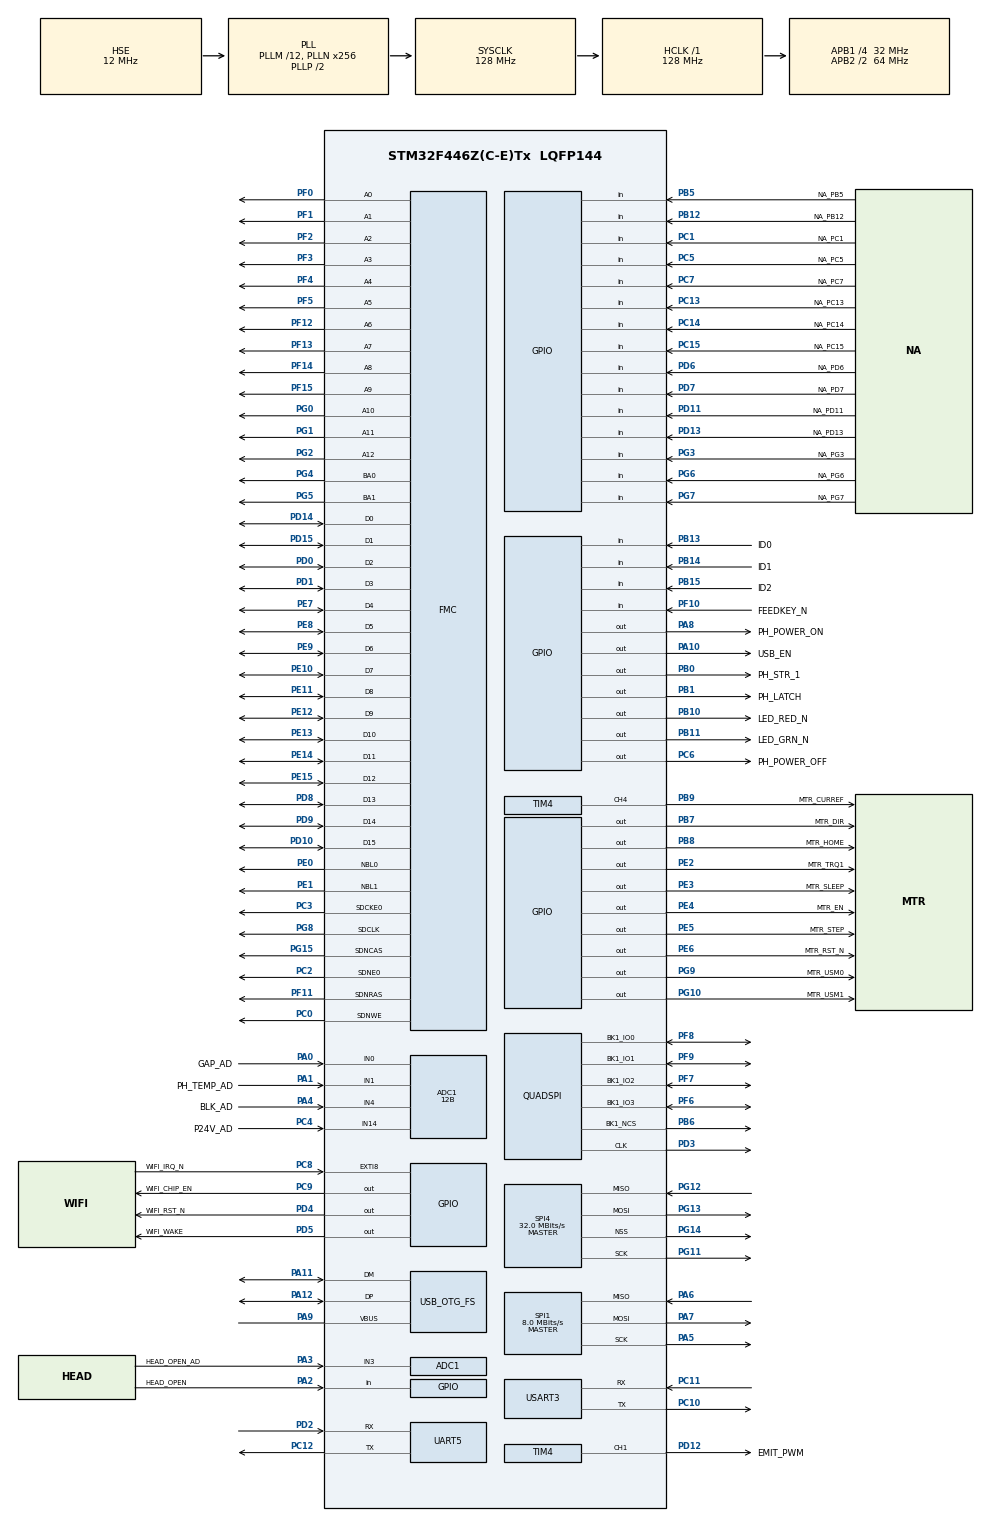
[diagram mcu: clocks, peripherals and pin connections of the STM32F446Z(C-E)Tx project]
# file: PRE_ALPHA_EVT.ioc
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ADC1.Channel-0\#ChannelRegularConversion=ADC_CHANNEL_0
ADC1.Channel-1\#ChannelRegularConversion=ADC_CHANNEL_1
ADC1.Channel-2\#ChannelRegularConversion=ADC_CHANNEL_3
ADC1.Channel-3\#ChannelRegularConversion=ADC_CHANNEL_14
ADC1.Channel-4\#ChannelRegularConversion=ADC_CHANNEL_TEMPSENSOR
ADC1.Channel-6\#ChannelRegularConversion=ADC_CHANNEL_4
ADC1.ClockPrescaler=ADC_CLOCK_SYNC_PCLK_DIV2
ADC1.ContinuousConvMode=ENABLE
ADC1.DMAContinuousRequests=ENABLE
ADC1.DataAlign=ADC_DATAALIGN_RIGHT
ADC1.DiscontinuousConvMode=DISABLE
ADC1.EOCSelection=ADC_EOC_SEQ_CONV
ADC1.EnableAnalogWatchDog=false
ADC1.ExternalTrigConv=ADC_SOFTWARE_START
ADC1.ExternalTrigConvEdge=ADC_EXTERNALTRIGCONVEDGE_NONE
ADC1.InjNumberOfConversion=0
ADC1.NbrOfConversion=6
ADC1.NbrOfConversionFlag=1
ADC1.Rank-0\#ChannelRegularConversion=1
ADC1.Rank-1\#ChannelRegularConversion=2
ADC1.Rank-2\#ChannelRegularConversion=3
ADC1.Rank-3\#ChannelRegularConversion=4
ADC1.Rank-4\#ChannelRegularConversion=5
ADC1.Rank-6\#ChannelRegularConversion=6
ADC1.Resolution=ADC_RESOLUTION_12B
ADC1.SamplingTime-0\#ChannelRegularConversion=ADC_SAMPLETIME_112CYCLES
ADC1.SamplingTime-1\#ChannelRegularConversion=ADC_SAMPLETIME_112CYCLES
ADC1.SamplingTime-2\#ChannelRegularConversion=ADC_SAMPLETIME_112CYCLES
ADC1.SamplingTime-3\#ChannelRegularConversion=ADC_SAMPLETIME_112CYCLES
ADC1.SamplingTime-4\#ChannelRegularConversion=ADC_SAMPLETIME_480CYCLES
ADC1.SamplingTime-6\#ChannelRegularConversion=ADC_SAMPLETIME_112CYCLES
ADC1.ScanConvMode=ENABLE
ADC1.master=1
Dma.ADC1.3.Direction=DMA_PERIPH_TO_MEMORY
Dma.ADC1.3.FIFOMode=DMA_FIFOMODE_DISABLE
Dma.ADC1.3.Instance=DMA2_Stream0
Dma.ADC1.3.MemDataAlignment=DMA_MDATAALIGN_WORD
Dma.ADC1.3.MemInc=DMA_MINC_ENABLE
Dma.ADC1.3.Mode=DMA_CIRCULAR
Dma.ADC1.3.PeriphDataAlignment=DMA_PDATAALIGN_WORD
Dma.ADC1.3.PeriphInc=DMA_PINC_DISABLE
Dma.ADC1.3.Priority=DMA_PRIORITY_VERY_HIGH
Dma.MEMTOMEM.0.Direction=DMA_MEMORY_TO_MEMORY
Dma.MEMTOMEM.0.FIFOMode=DMA_FIFOMODE_ENABLE
Dma.MEMTOMEM.0.FIFOThreshold=DMA_FIFO_THRESHOLD_FULL
Dma.MEMTOMEM.0.Instance=DMA2_Stream2
Dma.MEMTOMEM.0.MemBurst=DMA_MBURST_SINGLE
Dma.MEMTOMEM.0.MemDataAlignment=DMA_MDATAALIGN_WORD
Dma.MEMTOMEM.0.MemInc=DMA_MINC_ENABLE
Dma.MEMTOMEM.0.Mode=DMA_NORMAL
Dma.MEMTOMEM.0.PeriphBurst=DMA_PBURST_SINGLE
Dma.MEMTOMEM.0.PeriphDataAlignment=DMA_PDATAALIGN_WORD
Dma.MEMTOMEM.0.PeriphInc=DMA_PINC_ENABLE
Dma.MEMTOMEM.0.Priority=DMA_PRIORITY_MEDIUM
Dma.Request0=MEMTOMEM
Dma.Request1=SPI4_TX
Dma.Request2=SPI4_RX
Dma.Request3=ADC1
Dma.Request4=SPI1_TX
Dma.SPI1_TX.4.Direction=DMA_MEMORY_TO_PERIPH
Dma.SPI1_TX.4.FIFOMode=DMA_FIFOMODE_DISABLE
Dma.SPI1_TX.4.Instance=DMA2_Stream5
Dma.SPI1_TX.4.MemDataAlignment=DMA_MDATAALIGN_BYTE
Dma.SPI1_TX.4.MemInc=DMA_MINC_ENABLE
Dma.SPI1_TX.4.Mode=DMA_NORMAL
Dma.SPI1_TX.4.PeriphDataAlignment=DMA_PDATAALIGN_BYTE
Dma.SPI1_TX.4.PeriphInc=DMA_PINC_DISABLE
Dma.SPI1_TX.4.Priority=DMA_PRIORITY_HIGH
Dma.SPI4_RX.2.Direction=DMA_PERIPH_TO_MEMORY
Dma.SPI4_RX.2.FIFOMode=DMA_FIFOMODE_DISABLE
Dma.SPI4_RX.2.Instance=DMA2_Stream3
Dma.SPI4_RX.2.MemDataAlignment=DMA_MDATAALIGN_BYTE
Dma.SPI4_RX.2.MemInc=DMA_MINC_ENABLE
Dma.SPI4_RX.2.Mode=DMA_NORMAL
Dma.SPI4_RX.2.PeriphDataAlignment=DMA_PDATAALIGN_BYTE
Dma.SPI4_RX.2.PeriphInc=DMA_PINC_DISABLE
Dma.SPI4_RX.2.Priority=DMA_PRIORITY_LOW
Dma.SPI4_TX.1.Direction=DMA_MEMORY_TO_PERIPH
Dma.SPI4_TX.1.FIFOMode=DMA_FIFOMODE_DISABLE
Dma.SPI4_TX.1.Instance=DMA2_Stream4
Dma.SPI4_TX.1.MemDataAlignment=DMA_MDATAALIGN_BYTE
Dma.SPI4_TX.1.MemInc=DMA_MINC_ENABLE
Dma.SPI4_TX.1.Mode=DMA_NORMAL
Dma.SPI4_TX.1.PeriphDataAlignment=DMA_PDATAALIGN_BYTE
Dma.SPI4_TX.1.PeriphInc=DMA_PINC_DISABLE
Dma.SPI4_TX.1.Priority=DMA_PRIORITY_LOW
FMC.CASLatency1=FMC_SDRAM_CAS_LATENCY_3
FMC.ExitSelfRefreshDelay1=4
FMC.LoadToActiveDelay1=3
FMC.RCDDelay1=1
FMC.RPDelay1=1
FMC.RPDelay2=1
FMC.RowCycleDelay1=3
FMC.RowCycleDelay2=3
FMC.SDClockPeriod1=FMC_SDRAM_CLOCK_PERIOD_3
FMC.SDClockPeriod2=FMC_SDRAM_CLOCK_PERIOD_3
FMC.SelfRefreshTime1=2
FMC.WriteRecoveryTime1=2
Mcu.Family=STM32F4
Mcu.Name=STM32F446Z(C-E)Tx
Mcu.Package=LQFP144
NVIC.ADC_IRQn=true\:2\:0\:true\:false\:true\:true
NVIC.DMA2_Stream0_IRQn=true\:4\:0\:true\:false\:true\:false
NVIC.DMA2_Stream2_IRQn=true\:5\:0\:true\:false\:true\:true
NVIC.DMA2_Stream3_IRQn=true\:4\:0\:true\:false\:true\:false
NVIC.DMA2_Stream4_IRQn=true\:4\:0\:true\:false\:true\:false
NVIC.DMA2_Stream5_IRQn=true\:0\:0\:false\:false\:true\:false
NVIC.OTG_FS_IRQn=true\:3\:0\:true\:false\:true\:false
NVIC.PriorityGroup=NVIC_PRIORITYGROUP_4
NVIC.TIM2_IRQn=true\:3\:0\:true\:false\:true\:true
NVIC.TIM3_IRQn=true\:4\:0\:true\:false\:true\:true
NVIC.TIM5_IRQn=true\:4\:0\:true\:false\:true\:true
NVIC.USART3_IRQn=true\:0\:0\:false\:false\:true\:true
PA0-WKUP.GPIO_Label=GAP_AD
PA0-WKUP.Signal=ADCx_IN0
PA1.GPIO_Label=PH_TEMP_AD
PA1.Signal=ADCx_IN1
PA10.GPIO_Label=USB_EN
PA10.Signal=GPIO_Output
PA11.Mode=Device_Only
PA11.Signal=USB_OTG_FS_DM
PA12.Mode=Device_Only
PA12.Signal=USB_OTG_FS_DP
PA13.Mode=JTAG_5_pins
PA13.Signal=SYS_JTMS-SWDIO
PA14.Mode=JTAG_5_pins
PA14.Signal=SYS_JTCK-SWCLK
PA15.Mode=JTAG_5_pins
PA15.Signal=SYS_JTDI
PA2.GPIO_Label=HEAD_OPEN
PA2.Signal=GPIO_Input
PA3.GPIO_Label=HEAD_OPEN_AD
PA3.Signal=ADCx_IN3
PA4.GPIO_Label=BLK_AD
PA4.Signal=ADCx_IN4
PA5.Mode=Full_Duplex_Master
PA5.Signal=SPI1_SCK
PA6.Mode=Full_Duplex_Master
PA6.Signal=SPI1_MISO
PA7.Mode=Full_Duplex_Master
PA7.Signal=SPI1_MOSI
PA8.GPIO_Label=PH_POWER_ON
PA8.Signal=GPIO_Output
PA9.Mode=Activate_VBUS
PA9.Signal=USB_OTG_FS_VBUS
PB0.GPIO_Label=PH_STR_1
PB0.Signal=GPIO_Output
PB1.GPIO_Label=PH_LATCH
PB1.Signal=GPIO_Output
PB10.GPIO_Label=LED_RED_N
PB10.PinState=GPIO_PIN_SET
PB10.Signal=GPIO_Output
PB11.GPIO_Label=LED_GRN_N
PB11.PinState=GPIO_PIN_SET
PB11.Signal=GPIO_Output
PB12.GPIO_Label=NA_PB12
PB12.Signal=GPIO_Input
PB13.GPIO_Label=ID0
PB13.Signal=GPIO_Input
PB14.GPIO_Label=ID1
PB14.Signal=GPIO_Input
PB15.GPIO_Label=ID2
PB15.Signal=GPIO_Input
PB3.Mode=JTAG_5_pins
PB3.Signal=SYS_JTDO-SWO
PB4.Mode=JTAG_5_pins
PB4.Signal=SYS_JTRST
PB5.GPIO_Label=NA_PB5
PB5.Signal=GPIO_Input
PB6.Mode=Single Bank 1
PB6.Signal=QUADSPI_BK1_NCS
PB7.GPIO_Label=MTR_DIR
PB7.Signal=GPIO_Output
PB8.GPIO_Label=MTR_HOME
PB8.Signal=GPIO_Output
PB9.GPIO_Label=MTR_CURREF
PB9.GPIO_PuPd=GPIO_PULLUP
PB9.Signal=S_TIM4_CH4
PC0.Signal=FMC_SDNWE
PC1.GPIO_Label=NA_PC1
PC1.Signal=GPIO_Input
PC10.Mode=Asynchronous
PC10.Signal=USART3_TX
PC11.Mode=Asynchronous
PC11.Signal=USART3_RX
PC12.Mode=Asynchronous
PC12.Signal=UART5_TX
PC13.GPIO_Label=NA_PC13
PC13.Signal=GPIO_Input
PC14-OSC32_IN.GPIO_Label=NA_PC14
PC14-OSC32_IN.Signal=GPIO_Input
PC15-OSC32_OUT.GPIO_Label=NA_PC15
PC15-OSC32_OUT.Signal=GPIO_Input
PC2.Mode=SdramChipSelect1_1
PC2.Signal=FMC_SDNE0
PC3.Mode=SdramChipSelect1_1
PC3.Signal=FMC_SDCKE0
PC4.GPIO_Label=P24V_AD
PC4.Signal=ADCx_IN14
PC5.GPIO_Label=NA_PC5
PC5.Signal=GPIO_Input
PC6.GPIO_Label=PH_POWER_OFF
PC6.GPIO_PuPd=GPIO_PULLUP
PC6.Signal=GPIO_Output
PC7.GPIO_Label=NA_PC7
PC7.Signal=GPIO_Input
PC8.GPIO_Label=WIFI_IRQ_N
PC8.Signal=GPXTI8
PC9.GPIO_Label=WIFI_CHIP_EN
PC9.Signal=GPIO_Output
PD0.Signal=FMC_D2_DA2
PD1.Signal=FMC_D3_DA3
PD10.Signal=FMC_D15_DA15
PD11.GPIO_Label=NA_PD11
PD11.Signal=GPIO_Input
PD12.GPIO_Label=EMIT_PWM
PD12.GPIO_PuPd=GPIO_PULLUP
PD12.Signal=S_TIM4_CH1
PD13.GPIO_Label=NA_PD13
PD13.Signal=GPIO_Input
PD14.Signal=FMC_D0_DA0
PD15.Signal=FMC_D1_DA1
PD2.Mode=Asynchronous
PD2.Signal=UART5_RX
PD3.Mode=Single Bank 1
PD3.Signal=QUADSPI_CLK
PD4.GPIO_Label=WIFI_RST_N
PD4.Signal=GPIO_Output
PD5.GPIO_Label=WIFI_WAKE
PD5.Signal=GPIO_Output
PD6.GPIO_Label=NA_PD6
PD6.Signal=GPIO_Input
PD7.GPIO_Label=NA_PD7
PD7.Signal=GPIO_Input
PD8.Signal=FMC_D13_DA13
PD9.Signal=FMC_D14_DA14
PE0.Signal=FMC_NBL0
PE1.Signal=FMC_NBL1
PE10.Signal=FMC_D7_DA7
PE11.Signal=FMC_D8_DA8
PE12.Signal=FMC_D9_DA9
PE13.Signal=FMC_D10_DA10
PE14.Signal=FMC_D11_DA11
PE15.Signal=FMC_D12_DA12
PE2.GPIO_Label=MTR_TRQ1
PE2.Signal=GPIO_Output
PE3.GPIO_Label=MTR_SLEEP
PE3.Signal=GPIO_Output
PE4.GPIO_Label=MTR_EN
PE4.PinState=GPIO_PIN_SET
PE4.Signal=GPIO_Output
PE5.GPIO_Label=MTR_STEP
PE5.Signal=GPIO_Output
PE6.GPIO_Label=MTR_RST_N
PE6.PinState=GPIO_PIN_SET
PE6.Signal=GPIO_Output
PE7.Signal=FMC_D4_DA4
PE8.Signal=FMC_D5_DA5
PE9.Signal=FMC_D6_DA6
PF0.Signal=FMC_A0
PF1.Signal=FMC_A1
PF10.GPIO_Label=FEEDKEY_N
PF10.GPIO_PuPd=GPIO_PULLUP
PF10.Signal=GPIO_Input
PF11.Signal=FMC_SDNRAS
PF12.Signal=FMC_A6
PF13.Signal=FMC_A7
PF14.Signal=FMC_A8
PF15.Signal=FMC_A9
PF2.Signal=FMC_A2
PF3.Signal=FMC_A3
PF4.Signal=FMC_A4
PF5.Signal=FMC_A5
PF6.Mode=Single Bank 1
PF6.Signal=QUADSPI_BK1_IO3
PF7.Mode=Single Bank 1
PF7.Signal=QUADSPI_BK1_IO2
PF8.Mode=Single Bank 1
PF8.Signal=QUADSPI_BK1_IO0
PF9.Mode=Single Bank 1
PF9.Signal=QUADSPI_BK1_IO1
PG0.Signal=FMC_A10
PG1.Signal=FMC_A11
PG10.GPIO_Label=MTR_USM1
PG10.Signal=GPIO_Output
PG11.Mode=Full_Duplex_Master
PG11.Signal=SPI4_SCK
PG12.Mode=Full_Duplex_Master
PG12.Signal=SPI4_MISO
PG13.Mode=Full_Duplex_Master
PG13.Signal=SPI4_MOSI
PG14.Mode=NSS_Signal_Hard_Output
PG14.Signal=SPI4_NSS
PG15.Signal=FMC_SDNCAS
PG2.Signal=FMC_A12
PG3.GPIO_Label=NA_PG3
PG3.Signal=GPIO_Input
PG4.Signal=FMC_A14_BA0
PG5.Signal=FMC_A15_BA1
PG6.GPIO_Label=NA_PG6
PG6.Signal=GPIO_Input
PG7.GPIO_Label=NA_PG7
PG7.Signal=GPIO_Input
PG8.Signal=FMC_SDCLK
PG9.GPIO_Label=MTR_USM0
PG9.Signal=GPIO_Output
PH0-OSC_IN.Mode=HSE-External-Oscillator
PH0-OSC_IN.Signal=RCC_OSC_IN
PH1-OSC_OUT.Mode=HSE-External-Oscillator
PH1-OSC_OUT.Signal=RCC_OSC_OUT
ProjectManager.HeapSize=0x200
ProjectManager.StackSize=0x400
ProjectManager.TargetToolchain=SW4STM32
RCC.AHBFreq_Value=128000000
RCC.APB1CLKDivider=RCC_HCLK_DIV4
RCC.APB1Freq_Value=32000000
RCC.APB1TimFreq_Value=64000000
RCC.APB2CLKDivider=RCC_HCLK_DIV2
RCC.APB2Freq_Value=64000000
RCC.APB2TimFreq_Value=128000000
RCC.CortexFreq_Value=128000000
RCC.HCLKFreq_Value=128000000
RCC.HSE_VALUE=12000000
RCC.PLLM=12
RCC.PLLN=256
RCC.PLLQ=14
RCC.PLLSAIM=12
RCC.PLLSAIP=RCC_PLLSAIP_DIV4
RCC.SYSCLKFreq_VALUE=128000000
RCC.SYSCLKSource=RCC_SYSCLKSOURCE_PLLCLK
RCC.USBCLockSelection=RCC_CLK48CLKSOURCE_PLLSAIP
RCC.USBFreq_Value=48000000
RCC.VCOOutputFreq_Value=256000000
SH.ADCx_IN0.0=ADC1_IN0,IN0
SH.ADCx_IN1.0=ADC1_IN1,IN1
SH.ADCx_IN14.0=ADC1_IN14,IN14
SH.ADCx_IN3.0=ADC1_IN3,IN3
SH.ADCx_IN4.0=ADC1_IN4,IN4
SH.FMC_A0.0=FMC_A0,13b-sda1
SH.FMC_A1.0=FMC_A1,13b-sda1
SH.FMC_A10.0=FMC_A10,13b-sda1
SH.FMC_A11.0=FMC_A11,13b-sda1
SH.FMC_A12.0=FMC_A12,13b-sda1
SH.FMC_A14_BA0.0=FMC_BA0,FourSdramBanks1
SH.FMC_A15_BA1.0=FMC_BA1,FourSdramBanks1
SH.FMC_A2.0=FMC_A2,13b-sda1
SH.FMC_A3.0=FMC_A3,13b-sda1
SH.FMC_A4.0=FMC_A4,13b-sda1
SH.FMC_A5.0=FMC_A5,13b-sda1
SH.FMC_A6.0=FMC_A6,13b-sda1
SH.FMC_A7.0=FMC_A7,13b-sda1
SH.FMC_A8.0=FMC_A8,13b-sda1
SH.FMC_A9.0=FMC_A9,13b-sda1
SH.FMC_D0_DA0.0=FMC_D0,sd-16b-d1
SH.FMC_D10_DA10.0=FMC_D10,sd-16b-d1
SH.FMC_D11_DA11.0=FMC_D11,sd-16b-d1
SH.FMC_D12_DA12.0=FMC_D12,sd-16b-d1
SH.FMC_D13_DA13.0=FMC_D13,sd-16b-d1
SH.FMC_D14_DA14.0=FMC_D14,sd-16b-d1
SH.FMC_D15_DA15.0=FMC_D15,sd-16b-d1
SH.FMC_D1_DA1.0=FMC_D1,sd-16b-d1
SH.FMC_D2_DA2.0=FMC_D2,sd-16b-d1
SH.FMC_D3_DA3.0=FMC_D3,sd-16b-d1
SH.FMC_D4_DA4.0=FMC_D4,sd-16b-d1
SH.FMC_D5_DA5.0=FMC_D5,sd-16b-d1
SH.FMC_D6_DA6.0=FMC_D6,sd-16b-d1
SH.FMC_D7_DA7.0=FMC_D7,sd-16b-d1
SH.FMC_D8_DA8.0=FMC_D8,sd-16b-d1
SH.FMC_D9_DA9.0=FMC_D9,sd-16b-d1
SH.FMC_NBL0.0=FMC_NBL0,Sd2ByteEnable1
SH.FMC_NBL1.0=FMC_NBL1,Sd2ByteEnable1
SH.FMC_SDCLK.0=FMC_SDCLK,13b-sda1
SH.FMC_SDNCAS.0=FMC_SDNCAS,13b-sda1
SH.FMC_SDNRAS.0=FMC_SDNRAS,13b-sda1
SH.FMC_SDNWE.0=FMC_SDNWE,13b-sda1
SH.S_TIM4_CH1.0=TIM4_CH1,PWM Generation1 CH1
SH.S_TIM4_CH4.0=TIM4_CH4,PWM Generation4 CH4
SPI1.BaudRatePrescaler=SPI_BAUDRATEPRESCALER_8
SPI1.CLKPolarity=SPI_POLARITY_HIGH
SPI1.CalculateBaudRate=8.0 MBits/s
SPI1.Direction=SPI_DIRECTION_2LINES
SPI1.Mode=SPI_MODE_MASTER
SPI1.VirtualType=VM_MASTER
SPI4.BaudRatePrescaler=SPI_BAUDRATEPRESCALER_2
SPI4.CalculateBaudRate=32.0 MBits/s
SPI4.Direction=SPI_DIRECTION_2LINES
SPI4.Mode=SPI_MODE_MASTER
SPI4.VirtualNSS=VM_NSSHARD
SPI4.VirtualType=VM_MASTER
TIM2.Prescaler=31
TIM3.Period=2000
TIM3.Prescaler=31
TIM4.Channel-PWM\ Generation1\ CH1=TIM_CHANNEL_1
TIM4.Channel-PWM\ Generation4\ CH4=TIM_CHANNEL_4
TIM4.ClockDivision=TIM_CLOCKDIVISION_DIV1
TIM4.OCFastMode_PWM-PWM\ Generation1\ CH1=TIM_OCFAST_DISABLE
TIM4.OCFastMode_PWM-PWM\ Generation4\ CH4=TIM_OCFAST_DISABLE
TIM4.Period=200
TIM4.Prescaler=26
TIM4.Pulse-PWM\ Generation1\ CH1=10
TIM4.Pulse-PWM\ Generation4\ CH4=10
TIM5.Period=200
TIM5.Prescaler=31
UART5.VirtualMode=Asynchronous
USART3.VirtualMode=VM_ASYNC
USB_DEVICE.APP_RX_DATA_SIZE-CDC_FS=256
USB_DEVICE.APP_TX_DATA_SIZE-CDC_FS=256
USB_DEVICE.CLASS_NAME_FS=CDC
USB_DEVICE.VirtualMode-CDC_FS=Cdc
USB_DEVICE.VirtualModeFS=Cdc_FS
USB_OTG_FS.VirtualMode=Device_Only
VP_ADC1_TempSens_Input.Mode=IN-TempSens
VP_CRC_VS_CRC.Mode=CRC_Activate
VP_TIM2_VS_ClockSourceINT.Mode=Internal
VP_TIM3_VS_ClockSourceINT.Mode=Internal
VP_TIM4_VS_ClockSourceINT.Mode=Internal
VP_TIM5_VS_ClockSourceINT.Mode=Internal
VP_USB_DEVICE_VS_USB_DEVICE_CDC_FS.Mode=CDC_FS
board=PRE_ALPHA_EVT

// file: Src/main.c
/**
  ******************************************************************************
  * File Name          : main.c
  * Description        : Main program body
  ******************************************************************************
  * This notice applies to any and all portions of this file
  * that are not between comment pairs USER CODE BEGIN and
  * USER CODE END. Other portions of this file, whether
  * inserted by the user or by software development tools
  * are owned by their respective copyright owners.
  *
  * Copyright (c) 2017 STMicroelectronics International N.V.
  * All rights reserved.
  *
  * Redistribution and use in source and binary forms, with or without
  * modification, are permitted, provided that the following conditions are met:
  *
  * 1. Redistribution of source code must retain the above copyright notice,
  *    this list of conditions and the following disclaimer.
  * 2. Redistributions in binary form must reproduce the above copyright notice,
  *    this list of conditions and the following disclaimer in the documentation
  *    and/or other materials provided with the distribution.
  * 3. Neither the name of STMicroelectronics nor the names of other
  *    contributors to this software may be used to endorse or promote products
  *    derived from this software without specific written permission.
  * 4. This software, including modifications and/or derivative works of this
  *    software, must execute solely and exclusively on microcontroller or
  *    microprocessor devices manufactured by or for STMicroelectronics.
  * 5. Redistribution and use of this software other than as permitted under
  *    this license is void and will automatically terminate your rights under
  *    this license.
  *
  * THIS SOFTWARE IS PROVIDED BY STMICROELECTRONICS AND CONTRIBUTORS "AS IS"
  * AND ANY EXPRESS, IMPLIED OR STATUTORY WARRANTIES, INCLUDING, BUT NOT
  * LIMITED TO, THE IMPLIED WARRANTIES OF MERCHANTABILITY, FITNESS FOR A
  * PARTICULAR PURPOSE AND NON-INFRINGEMENT OF THIRD PARTY INTELLECTUAL PROPERTY
  * RIGHTS ARE DISCLAIMED TO THE FULLEST EXTENT PERMITTED BY LAW. IN NO EVENT
  * SHALL STMICROELECTRONICS OR CONTRIBUTORS BE LIABLE FOR ANY DIRECT, INDIRECT,
  * INCIDENTAL, SPECIAL, EXEMPLARY, OR CONSEQUENTIAL DAMAGES (INCLUDING, BUT NOT
  * LIMITED TO, PROCUREMENT OF SUBSTITUTE GOODS OR SERVICES; LOSS OF USE, DATA,
  * OR PROFITS; OR BUSINESS INTERRUPTION) HOWEVER CAUSED AND ON ANY THEORY OF
  * LIABILITY, WHETHER IN CONTRACT, STRICT LIABILITY, OR TORT (INCLUDING
  * NEGLIGENCE OR OTHERWISE) ARISING IN ANY WAY OUT OF THE USE OF THIS SOFTWARE,
  * EVEN IF ADVISED OF THE POSSIBILITY OF SUCH DAMAGE.
  *
  ******************************************************************************
  */

#include "main.h"
#include "stm32f4xx_hal.h"
#include "usb_device.h"

/* USER CODE BEGIN Includes */
#include <stdio.h>
#include "comm_handle.h"
#include "misc.h"
#include "mem_handle.h"
#include "thermal_print.h"
#include "sensor_handle.h"
#include "test_mod.h"
/* USER CODE END Includes */

ADC_HandleTypeDef hadc1;
DMA_HandleTypeDef hdma_adc1;

CRC_HandleTypeDef hcrc;

QSPI_HandleTypeDef hqspi;

SPI_HandleTypeDef hspi1;
SPI_HandleTypeDef hspi4;
DMA_HandleTypeDef hdma_spi1_tx;
DMA_HandleTypeDef hdma_spi4_tx;
DMA_HandleTypeDef hdma_spi4_rx;

TIM_HandleTypeDef htim2;
TIM_HandleTypeDef htim3;
TIM_HandleTypeDef htim4;
TIM_HandleTypeDef htim5;

UART_HandleTypeDef huart5;
UART_HandleTypeDef huart3;

DMA_HandleTypeDef hdma_memtomem_dma2_stream2;
SDRAM_HandleTypeDef hsdram1;

/* USER CODE BEGIN PV */
/* Private variables ---------------------------------------------------------*/

/* USER CODE END PV */

void SystemClock_Config(void);
static void MX_GPIO_Init(void);
static void MX_DMA_Init(void);
static void MX_FMC_Init(void);
static void MX_ADC1_Init(void);
static void MX_SPI1_Init(void);
static void MX_QUADSPI_Init(void);
static void MX_USART3_UART_Init(void);
static void MX_UART5_Init(void);
static void MX_SPI4_Init(void);
static void MX_TIM4_Init(void);
static void MX_CRC_Init(void);
static void MX_TIM2_Init(void);
static void MX_TIM3_Init(void);
static void MX_TIM5_Init(void);

void HAL_TIM_MspPostInit(TIM_HandleTypeDef *htim);

/* USER CODE BEGIN PFP */
/* Private function prototypes -----------------------------------------------*/

/* USER CODE END PFP */

int main(void)
{

  /* USER CODE BEGIN 1 */
	uint8_t	u8Rev;
	uint8_t u8Temp;
#ifdef DEBUG_IS_ON
	DebugSwitch = PH_WD_ON|PH_SPI_ON;
#endif
  /* USER CODE END 1 */

  /* MCU Configuration----------------------------------------------------------*/

  /* Reset of all peripherals, Initializes the Flash interface and the Systick. */
  HAL_Init();

  /* Configure the system clock */
  SystemClock_Config();

  /* Initialize all configured peripherals */
  MX_GPIO_Init();
  MX_DMA_Init();
  MX_FMC_Init();
  MX_ADC1_Init();
  MX_SPI1_Init();
  MX_QUADSPI_Init();
  MX_USART3_UART_Init();
  MX_UART5_Init();
  MX_SPI4_Init();
  MX_TIM4_Init();
  MX_USB_DEVICE_Init();
  MX_CRC_Init();
  MX_TIM2_Init();
  MX_TIM3_Init();
  MX_TIM5_Init();

  /* USER CODE BEGIN 2 */
  //SDRAM_Buff_Init();
  LogBuf_Init();
  u8Rev = 96;
  SDRAM_Initialization_Sequence(&hsdram1, &SDRAMcommand);
  HAL_GPIO_WritePin(USB_EN_GPIO_Port,USB_EN_Pin,GPIO_PIN_SET);
  HAL_Delay(500);
  sprintf((char*)u8TxBuf, "This is Pre-alpha test program Ver.0.%d\r\n", u8Rev);
  Debug_Msg_Out((char*)u8TxBuf);
  HAL_Delay(100);
  sprintf((char*)u8TxBuf, "PH SPI port freq is %d MHz\r\n", (int)PH_SPICLK_MHZ);
  Debug_Msg_Out((char*)u8TxBuf);
  HAL_Delay(500);
  sprintf((char*)u8TxBuf, "SDRAM freq is %d00 Hz\r\n", (int)SDRAM_FREQ);
  Debug_Msg_Out((char*)u8TxBuf);
  u8Temp = SDRAM_Verification(&hdma_memtomem_dma2_stream2,(uint32_t *)(&u8Image[0][0]), (uint32_t *)(SDRAM_BANK_ADDR), 32448);
  if(u8Temp){
	  //return >0
	  sprintf((char*)u8TxBuf, "SDRAM R/W err:%d\r\n", u8Temp);
  }else{
	  //return 0
	  sprintf((char*)u8TxBuf, "SDRAM R/W done\r\n");
  }
  Debug_Msg_Out((char*)u8TxBuf);

  HAL_ADC_Start_DMA(&hadc1, &u32ADTemp[0][0], 18);

  PrintEng_Init();

  /* USER CODE END 2 */

  /* Infinite loop */
  /* USER CODE BEGIN WHILE */
  while (1)
  {

	  if(u16TimerSlotCounter & TIME_SLOT_COUNTER_BIT_01){
		  u16TimerSlotCounter ^= TIME_SLOT_COUNTER_BIT_01;
		  /* Time_Slot_01 function here called every 2ms */

	  }
	  if(u16TimerSlotCounter & TIME_SLOT_COUNTER_BIT_02){
		  u16TimerSlotCounter ^= TIME_SLOT_COUNTER_BIT_02;
		  /* Time_Slot_02 function here called every 4ms */
		  Head_Open_Detection(&u32ADFiltered[ADQ_HEADOPEN]);
		  LED_Rreshing();
		  Feed_Key_Sampling();
	  }
	  if(u16TimerSlotCounter & TIME_SLOT_COUNTER_BIT_03)
	  {
		  u16TimerSlotCounter ^= TIME_SLOT_COUNTER_BIT_03;
		  /* Time_Slot_03 function here called every 8ms */
	  }
	  if(u16TimerSlotCounter & TIME_SLOT_COUNTER_BIT_04)
	  {
		  u16TimerSlotCounter ^= TIME_SLOT_COUNTER_BIT_04;
		  /* Time_Slot_04 function here called every 16ms */
	  }
	  if(u16TimerSlotCounter & TIME_SLOT_COUNTER_BIT_05)
	  {
		  u16TimerSlotCounter ^= TIME_SLOT_COUNTER_BIT_05;
		  /* Time_Slot_05 function here called every 32ms */
		  PrintTask_Handler();
		  Label_Loader(u8PrintTestMod,0);

	  }
	  if(u16TimerSlotCounter & TIME_SLOT_COUNTER_BIT_06)
	  {
		  u16TimerSlotCounter ^= TIME_SLOT_COUNTER_BIT_06;
		  /* Time_Slot_05 function here called every 64ms */

	  }
	  if(u16TimerSlotCounter & TIME_SLOT_COUNTER_BIT_07)
	  {
		  u16TimerSlotCounter ^= TIME_SLOT_COUNTER_BIT_07;
		  /* Time_Slot_05 function here called every 128ms */
		  USB_Receive();
	  }
	  if(u16TimerSlotCounter & TIME_SLOT_COUNTER_BIT_08)
	  {
		  u16TimerSlotCounter ^= TIME_SLOT_COUNTER_BIT_08;
		  /* Time_Slot_05 function here called every 256ms */
		  if(SensorData.u8CalibState & CALIB_WITH_SWATCH){
			  Calib_Intensity();
		  }else{
			  Label_Calib();
		  }
	  }
	  if(u16TimerSlotCounter & TIME_SLOT_COUNTER_BIT_09)
	  {
		  u16TimerSlotCounter ^= TIME_SLOT_COUNTER_BIT_09;
		  /* Time_Slot_05 function here called every 512ms */
		  //HAL_GPIO_TogglePin(LED_GRN_N_GPIO_Port,LED_GRN_N_Pin);
	  }
	  if(u16TimerSlotCounter & TIME_SLOT_COUNTER_BIT_10)
	  {
		  u16TimerSlotCounter ^= TIME_SLOT_COUNTER_BIT_10;
		  /* Time_Slot_05 function here called every 1024ms */
	  }
	  if(u16TimerSlotCounter & TIME_SLOT_COUNTER_BIT_11)
	  {
		  u16TimerSlotCounter ^= TIME_SLOT_COUNTER_BIT_11;
		  /* Time_Slot_05 function here called every 2048ms */

	  }
	  if(u16TimerSlotCounter & TIME_SLOT_COUNTER_BIT_12)
	  {
		  u16TimerSlotCounter ^= TIME_SLOT_COUNTER_BIT_12;
		  /* Time_Slot_05 function here called every 4096ms */
	  }
	  if(u16TimerSlotCounter & TIME_SLOT_COUNTER_BIT_13)
	  {
		  u16TimerSlotCounter ^= TIME_SLOT_COUNTER_BIT_13;
		  /* Time_Slot_05 function here called every 8192ms */
	  }
	  if(u16TimerSlotCounter & TIME_SLOT_COUNTER_BIT_14)
	  {
		  u16TimerSlotCounter ^= TIME_SLOT_COUNTER_BIT_14;
		  /* Time_Slot_05 function here called every 16384ms */
	  }
	  if(u16TimerSlotCounter & TIME_SLOT_COUNTER_BIT_15){
		  u16TimerSlotCounter ^= TIME_SLOT_COUNTER_BIT_15;
		  /* Time_Slot_05 function here called every 32768ms */

	  }
  /* USER CODE END WHILE */

  }

}

/** System Clock Configuration
*/
void SystemClock_Config(void)
{

  RCC_OscInitTypeDef RCC_OscInitStruct;
  RCC_ClkInitTypeDef RCC_ClkInitStruct;
  RCC_PeriphCLKInitTypeDef PeriphClkInitStruct;

    /**Configure the main internal regulator output voltage
    */
  __HAL_RCC_PWR_CLK_ENABLE();

  __HAL_PWR_VOLTAGESCALING_CONFIG(PWR_REGULATOR_VOLTAGE_SCALE2);

    /**Initializes the CPU, AHB and APB busses clocks
    */
  RCC_OscInitStruct.OscillatorType = RCC_OSCILLATORTYPE_HSE;
  RCC_OscInitStruct.HSEState = RCC_HSE_ON;
  RCC_OscInitStruct.PLL.PLLState = RCC_PLL_ON;
  RCC_OscInitStruct.PLL.PLLSource = RCC_PLLSOURCE_HSE;
  RCC_OscInitStruct.PLL.PLLM = 12;
  RCC_OscInitStruct.PLL.PLLN = 256;
  RCC_OscInitStruct.PLL.PLLP = RCC_PLLP_DIV2;
  RCC_OscInitStruct.PLL.PLLQ = 14;
  RCC_OscInitStruct.PLL.PLLR = 2;
  if (HAL_RCC_OscConfig(&RCC_OscInitStruct) != HAL_OK)
  {
    _Error_Handler(__FILE__, __LINE__);
  }

    /**Initializes the CPU, AHB and APB busses clocks
    */
  RCC_ClkInitStruct.ClockType = RCC_CLOCKTYPE_HCLK|RCC_CLOCKTYPE_SYSCLK
                              |RCC_CLOCKTYPE_PCLK1|RCC_CLOCKTYPE_PCLK2;
  RCC_ClkInitStruct.SYSCLKSource = RCC_SYSCLKSOURCE_PLLCLK;
  RCC_ClkInitStruct.AHBCLKDivider = RCC_SYSCLK_DIV1;
  RCC_ClkInitStruct.APB1CLKDivider = RCC_HCLK_DIV4;
  RCC_ClkInitStruct.APB2CLKDivider = RCC_HCLK_DIV2;

  if (HAL_RCC_ClockConfig(&RCC_ClkInitStruct, FLASH_LATENCY_4) != HAL_OK)
  {
    _Error_Handler(__FILE__, __LINE__);
  }

  PeriphClkInitStruct.PeriphClockSelection = RCC_PERIPHCLK_CLK48;
  PeriphClkInitStruct.PLLSAI.PLLSAIM = 12;
  PeriphClkInitStruct.PLLSAI.PLLSAIN = 192;
  PeriphClkInitStruct.PLLSAI.PLLSAIQ = 2;
  PeriphClkInitStruct.PLLSAI.PLLSAIP = RCC_PLLSAIP_DIV4;
  PeriphClkInitStruct.PLLSAIDivQ = 1;
  PeriphClkInitStruct.Clk48ClockSelection = RCC_CLK48CLKSOURCE_PLLSAIP;
  if (HAL_RCCEx_PeriphCLKConfig(&PeriphClkInitStruct) != HAL_OK)
  {
    _Error_Handler(__FILE__, __LINE__);
  }

    /**Configure the Systick interrupt time
    */
  HAL_SYSTICK_Config(HAL_RCC_GetHCLKFreq()/1000);

    /**Configure the Systick
    */
  HAL_SYSTICK_CLKSourceConfig(SYSTICK_CLKSOURCE_HCLK);

  /* SysTick_IRQn interrupt configuration */
  HAL_NVIC_SetPriority(SysTick_IRQn, 1, 0);
}

/* ADC1 init function */
static void MX_ADC1_Init(void)
{

  ADC_ChannelConfTypeDef sConfig;

    /**Configure the global features of the ADC (Clock, Resolution, Data Alignment and number of conversion)
    */
  hadc1.Instance = ADC1;
  hadc1.Init.ClockPrescaler = ADC_CLOCK_SYNC_PCLK_DIV2;
  hadc1.Init.Resolution = ADC_RESOLUTION_12B;
  hadc1.Init.ScanConvMode = ENABLE;
  hadc1.Init.ContinuousConvMode = ENABLE;
  hadc1.Init.DiscontinuousConvMode = DISABLE;
  hadc1.Init.ExternalTrigConvEdge = ADC_EXTERNALTRIGCONVEDGE_NONE;
  hadc1.Init.ExternalTrigConv = ADC_SOFTWARE_START;
  hadc1.Init.DataAlign = ADC_DATAALIGN_RIGHT;
  hadc1.Init.NbrOfConversion = 6;
  hadc1.Init.DMAContinuousRequests = ENABLE;
  hadc1.Init.EOCSelection = ADC_EOC_SEQ_CONV;
  if (HAL_ADC_Init(&hadc1) != HAL_OK)
  {
    _Error_Handler(__FILE__, __LINE__);
  }

    /**Configure for the selected ADC regular channel its corresponding rank in the sequencer and its sample time.
    */
  sConfig.Channel = ADC_CHANNEL_0;
  sConfig.Rank = 1;
  sConfig.SamplingTime = ADC_SAMPLETIME_112CYCLES;
  if (HAL_ADC_ConfigChannel(&hadc1, &sConfig) != HAL_OK)
  {
    _Error_Handler(__FILE__, __LINE__);
  }

    /**Configure for the selected ADC regular channel its corresponding rank in the sequencer and its sample time.
    */
  sConfig.Channel = ADC_CHANNEL_1;
  sConfig.Rank = 2;
  if (HAL_ADC_ConfigChannel(&hadc1, &sConfig) != HAL_OK)
  {
    _Error_Handler(__FILE__, __LINE__);
  }

    /**Configure for the selected ADC regular channel its corresponding rank in the sequencer and its sample time.
    */
  sConfig.Channel = ADC_CHANNEL_3;
  sConfig.Rank = 3;
  if (HAL_ADC_ConfigChannel(&hadc1, &sConfig) != HAL_OK)
  {
    _Error_Handler(__FILE__, __LINE__);
  }

    /**Configure for the selected ADC regular channel its corresponding rank in the sequencer and its sample time.
    */
  sConfig.Channel = ADC_CHANNEL_14;
  sConfig.Rank = 4;
  if (HAL_ADC_ConfigChannel(&hadc1, &sConfig) != HAL_OK)
  {
    _Error_Handler(__FILE__, __LINE__);
  }

    /**Configure for the selected ADC regular channel its corresponding rank in the sequencer and its sample time.
    */
  sConfig.Channel = ADC_CHANNEL_TEMPSENSOR;
  sConfig.Rank = 5;
  sConfig.SamplingTime = ADC_SAMPLETIME_480CYCLES;
  if (HAL_ADC_ConfigChannel(&hadc1, &sConfig) != HAL_OK)
  {
    _Error_Handler(__FILE__, __LINE__);
  }

    /**Configure for the selected ADC regular channel its corresponding rank in the sequencer and its sample time.
    */
  sConfig.Channel = ADC_CHANNEL_4;
  sConfig.Rank = 6;
  sConfig.SamplingTime = ADC_SAMPLETIME_112CYCLES;
  if (HAL_ADC_ConfigChannel(&hadc1, &sConfig) != HAL_OK)
  {
    _Error_Handler(__FILE__, __LINE__);
  }

}

/* CRC init function */
static void MX_CRC_Init(void)
{

  hcrc.Instance = CRC;
  if (HAL_CRC_Init(&hcrc) != HAL_OK)
  {
    _Error_Handler(__FILE__, __LINE__);
  }

}

/* QUADSPI init function */
static void MX_QUADSPI_Init(void)
{

  /* QUADSPI parameter configuration*/
  hqspi.Instance = QUADSPI;
  hqspi.Init.ClockPrescaler = 255;
  hqspi.Init.FifoThreshold = 1;
  hqspi.Init.SampleShifting = QSPI_SAMPLE_SHIFTING_NONE;
  hqspi.Init.FlashSize = 1;
  hqspi.Init.ChipSelectHighTime = QSPI_CS_HIGH_TIME_1_CYCLE;
  hqspi.Init.ClockMode = QSPI_CLOCK_MODE_0;
  hqspi.Init.FlashID = QSPI_FLASH_ID_1;
  hqspi.Init.DualFlash = QSPI_DUALFLASH_DISABLE;
  if (HAL_QSPI_Init(&hqspi) != HAL_OK)
  {
    _Error_Handler(__FILE__, __LINE__);
  }

}

/* SPI1 init function */
static void MX_SPI1_Init(void)
{

  /* SPI1 parameter configuration*/
  hspi1.Instance = SPI1;
  hspi1.Init.Mode = SPI_MODE_MASTER;
  hspi1.Init.Direction = SPI_DIRECTION_2LINES;
  hspi1.Init.DataSize = SPI_DATASIZE_8BIT;
  hspi1.Init.CLKPolarity = SPI_POLARITY_HIGH;
  hspi1.Init.CLKPhase = SPI_PHASE_1EDGE;
  hspi1.Init.NSS = SPI_NSS_SOFT;
  hspi1.Init.BaudRatePrescaler = SPI_BAUDRATEPRESCALER_16;
  hspi1.Init.FirstBit = SPI_FIRSTBIT_MSB;
  hspi1.Init.TIMode = SPI_TIMODE_DISABLE;
  hspi1.Init.CRCCalculation = SPI_CRCCALCULATION_DISABLE;
  hspi1.Init.CRCPolynomial = 10;
  if (HAL_SPI_Init(&hspi1) != HAL_OK)
  {
    _Error_Handler(__FILE__, __LINE__);
  }

}

/* SPI4 init function */
static void MX_SPI4_Init(void)
{

  /* SPI4 parameter configuration*/
  hspi4.Instance = SPI4;
  hspi4.Init.Mode = SPI_MODE_MASTER;
  hspi4.Init.Direction = SPI_DIRECTION_2LINES;
  hspi4.Init.DataSize = SPI_DATASIZE_8BIT;
  hspi4.Init.CLKPolarity = SPI_POLARITY_LOW;
  hspi4.Init.CLKPhase = SPI_PHASE_1EDGE;
  hspi4.Init.NSS = SPI_NSS_HARD_OUTPUT;
  hspi4.Init.BaudRatePrescaler = SPI_BAUDRATEPRESCALER_2;
  hspi4.Init.FirstBit = SPI_FIRSTBIT_MSB;
  hspi4.Init.TIMode = SPI_TIMODE_DISABLE;
  hspi4.Init.CRCCalculation = SPI_CRCCALCULATION_DISABLE;
  hspi4.Init.CRCPolynomial = 10;
  if (HAL_SPI_Init(&hspi4) != HAL_OK)
  {
    _Error_Handler(__FILE__, __LINE__);
  }

}

/* TIM2 init function */
static void MX_TIM2_Init(void)
{

  TIM_ClockConfigTypeDef sClockSourceConfig;
  TIM_MasterConfigTypeDef sMasterConfig;

  htim2.Instance = TIM2;
  htim2.Init.Prescaler = 31;
  htim2.Init.CounterMode = TIM_COUNTERMODE_UP;
  htim2.Init.Period = 0;
  htim2.Init.ClockDivision = TIM_CLOCKDIVISION_DIV1;
  if (HAL_TIM_Base_Init(&htim2) != HAL_OK)
  {
    _Error_Handler(__FILE__, __LINE__);
  }

  sClockSourceConfig.ClockSource = TIM_CLOCKSOURCE_INTERNAL;
  if (HAL_TIM_ConfigClockSource(&htim2, &sClockSourceConfig) != HAL_OK)
  {
    _Error_Handler(__FILE__, __LINE__);
  }

  sMasterConfig.MasterOutputTrigger = TIM_TRGO_RESET;
  sMasterConfig.MasterSlaveMode = TIM_MASTERSLAVEMODE_DISABLE;
  if (HAL_TIMEx_MasterConfigSynchronization(&htim2, &sMasterConfig) != HAL_OK)
  {
    _Error_Handler(__FILE__, __LINE__);
  }

}

/* TIM3 init function */
static void MX_TIM3_Init(void)
{

  TIM_ClockConfigTypeDef sClockSourceConfig;
  TIM_MasterConfigTypeDef sMasterConfig;

  htim3.Instance = TIM3;
  htim3.Init.Prescaler = 31;
  htim3.Init.CounterMode = TIM_COUNTERMODE_UP;
  htim3.Init.Period = 2000;
  htim3.Init.ClockDivision = TIM_CLOCKDIVISION_DIV1;
  if (HAL_TIM_Base_Init(&htim3) != HAL_OK)
  {
    _Error_Handler(__FILE__, __LINE__);
  }

  sClockSourceConfig.ClockSource = TIM_CLOCKSOURCE_INTERNAL;
  if (HAL_TIM_ConfigClockSource(&htim3, &sClockSourceConfig) != HAL_OK)
  {
    _Error_Handler(__FILE__, __LINE__);
  }

  sMasterConfig.MasterOutputTrigger = TIM_TRGO_RESET;
  sMasterConfig.MasterSlaveMode = TIM_MASTERSLAVEMODE_DISABLE;
  if (HAL_TIMEx_MasterConfigSynchronization(&htim3, &sMasterConfig) != HAL_OK)
  {
    _Error_Handler(__FILE__, __LINE__);
  }

}

/* TIM4 init function */
static void MX_TIM4_Init(void)
{

  TIM_ClockConfigTypeDef sClockSourceConfig;
  TIM_MasterConfigTypeDef sMasterConfig;
  TIM_OC_InitTypeDef sConfigOC;

  htim4.Instance = TIM4;
  htim4.Init.Prescaler = 26;
  htim4.Init.CounterMode = TIM_COUNTERMODE_UP;
  htim4.Init.Period = 200;
  htim4.Init.ClockDivision = TIM_CLOCKDIVISION_DIV1;
  if (HAL_TIM_Base_Init(&htim4) != HAL_OK)
  {
    _Error_Handler(__FILE__, __LINE__);
  }

  sClockSourceConfig.ClockSource = TIM_CLOCKSOURCE_INTERNAL;
  if (HAL_TIM_ConfigClockSource(&htim4, &sClockSourceConfig) != HAL_OK)
  {
    _Error_Handler(__FILE__, __LINE__);
  }

  if (HAL_TIM_PWM_Init(&htim4) != HAL_OK)
  {
    _Error_Handler(__FILE__, __LINE__);
  }

  sMasterConfig.MasterOutputTrigger = TIM_TRGO_RESET;
  sMasterConfig.MasterSlaveMode = TIM_MASTERSLAVEMODE_DISABLE;
  if (HAL_TIMEx_MasterConfigSynchronization(&htim4, &sMasterConfig) != HAL_OK)
  {
    _Error_Handler(__FILE__, __LINE__);
  }

  sConfigOC.OCMode = TIM_OCMODE_PWM1;
  sConfigOC.Pulse = 10;
  sConfigOC.OCPolarity = TIM_OCPOLARITY_HIGH;
  sConfigOC.OCFastMode = TIM_OCFAST_DISABLE;
  if (HAL_TIM_PWM_ConfigChannel(&htim4, &sConfigOC, TIM_CHANNEL_1) != HAL_OK)
  {
    _Error_Handler(__FILE__, __LINE__);
  }

  if (HAL_TIM_PWM_ConfigChannel(&htim4, &sConfigOC, TIM_CHANNEL_4) != HAL_OK)
  {
    _Error_Handler(__FILE__, __LINE__);
  }

  HAL_TIM_MspPostInit(&htim4);

}

/* TIM5 init function */
static void MX_TIM5_Init(void)
{

  TIM_ClockConfigTypeDef sClockSourceConfig;
  TIM_MasterConfigTypeDef sMasterConfig;

  htim5.Instance = TIM5;
  htim5.Init.Prescaler = 31;
  htim5.Init.CounterMode = TIM_COUNTERMODE_UP;
  htim5.Init.Period = 200;
  htim5.Init.ClockDivision = TIM_CLOCKDIVISION_DIV1;
  if (HAL_TIM_Base_Init(&htim5) != HAL_OK)
  {
    _Error_Handler(__FILE__, __LINE__);
  }

  sClockSourceConfig.ClockSource = TIM_CLOCKSOURCE_INTERNAL;
  if (HAL_TIM_ConfigClockSource(&htim5, &sClockSourceConfig) != HAL_OK)
  {
    _Error_Handler(__FILE__, __LINE__);
  }

  sMasterConfig.MasterOutputTrigger = TIM_TRGO_RESET;
  sMasterConfig.MasterSlaveMode = TIM_MASTERSLAVEMODE_DISABLE;
  if (HAL_TIMEx_MasterConfigSynchronization(&htim5, &sMasterConfig) != HAL_OK)
  {
    _Error_Handler(__FILE__, __LINE__);
  }

}

/* UART5 init function */
static void MX_UART5_Init(void)
{

  huart5.Instance = UART5;
  huart5.Init.BaudRate = 115200;
  huart5.Init.WordLength = UART_WORDLENGTH_8B;
  huart5.Init.StopBits = UART_STOPBITS_1;
  huart5.Init.Parity = UART_PARITY_NONE;
  huart5.Init.Mode = UART_MODE_TX_RX;
  huart5.Init.HwFlowCtl = UART_HWCONTROL_NONE;
  huart5.Init.OverSampling = UART_OVERSAMPLING_16;
  if (HAL_UART_Init(&huart5) != HAL_OK)
  {
    _Error_Handler(__FILE__, __LINE__);
  }

}

/* USART3 init function */
static void MX_USART3_UART_Init(void)
{

  huart3.Instance = USART3;
  huart3.Init.BaudRate = 115200;
  huart3.Init.WordLength = UART_WORDLENGTH_8B;
  huart3.Init.StopBits = UART_STOPBITS_1;
  huart3.Init.Parity = UART_PARITY_NONE;
  huart3.Init.Mode = UART_MODE_TX_RX;
  huart3.Init.HwFlowCtl = UART_HWCONTROL_NONE;
  huart3.Init.OverSampling = UART_OVERSAMPLING_16;
  if (HAL_UART_Init(&huart3) != HAL_OK)
  {
    _Error_Handler(__FILE__, __LINE__);
  }

}

static void MX_DMA_Init(void)
{
  /* DMA controller clock enable */
  __HAL_RCC_DMA2_CLK_ENABLE();

  /* Configure DMA request hdma_memtomem_dma2_stream2 on DMA2_Stream2 */
  hdma_memtomem_dma2_stream2.Instance = DMA2_Stream2;
  hdma_memtomem_dma2_stream2.Init.Channel = DMA_CHANNEL_0;
  hdma_memtomem_dma2_stream2.Init.Direction = DMA_MEMORY_TO_MEMORY;
  hdma_memtomem_dma2_stream2.Init.PeriphInc = DMA_PINC_ENABLE;
  hdma_memtomem_dma2_stream2.Init.MemInc = DMA_MINC_ENABLE;
  hdma_memtomem_dma2_stream2.Init.PeriphDataAlignment = DMA_PDATAALIGN_WORD;
  hdma_memtomem_dma2_stream2.Init.MemDataAlignment = DMA_MDATAALIGN_WORD;
  hdma_memtomem_dma2_stream2.Init.Mode = DMA_NORMAL;
  hdma_memtomem_dma2_stream2.Init.Priority = DMA_PRIORITY_MEDIUM;
  hdma_memtomem_dma2_stream2.Init.FIFOMode = DMA_FIFOMODE_ENABLE;
  hdma_memtomem_dma2_stream2.Init.FIFOThreshold = DMA_FIFO_THRESHOLD_FULL;
  hdma_memtomem_dma2_stream2.Init.MemBurst = DMA_MBURST_SINGLE;
  hdma_memtomem_dma2_stream2.Init.PeriphBurst = DMA_PBURST_SINGLE;
  if (HAL_DMA_Init(&hdma_memtomem_dma2_stream2) != HAL_OK)
  {
    _Error_Handler(__FILE__, __LINE__);
  }

  /* DMA interrupt init */
  /* DMA2_Stream0_IRQn interrupt configuration */
  HAL_NVIC_SetPriority(DMA2_Stream0_IRQn, 4, 0);
  HAL_NVIC_EnableIRQ(DMA2_Stream0_IRQn);
  /* DMA2_Stream2_IRQn interrupt configuration */
  HAL_NVIC_SetPriority(DMA2_Stream2_IRQn, 5, 0);
  HAL_NVIC_EnableIRQ(DMA2_Stream2_IRQn);
  /* DMA2_Stream3_IRQn interrupt configuration */
  HAL_NVIC_SetPriority(DMA2_Stream3_IRQn, 4, 0);
  HAL_NVIC_EnableIRQ(DMA2_Stream3_IRQn);
  /* DMA2_Stream4_IRQn interrupt configuration */
  HAL_NVIC_SetPriority(DMA2_Stream4_IRQn, 4, 0);
  HAL_NVIC_EnableIRQ(DMA2_Stream4_IRQn);
  /* DMA2_Stream5_IRQn interrupt configuration */
  HAL_NVIC_SetPriority(DMA2_Stream5_IRQn, 0, 0);
  HAL_NVIC_EnableIRQ(DMA2_Stream5_IRQn);

}
/* FMC initialization function */
static void MX_FMC_Init(void)
{
  FMC_SDRAM_TimingTypeDef SdramTiming;

  /** Perform the SDRAM1 memory initialization sequence
  */
  hsdram1.Instance = FMC_SDRAM_DEVICE;
  /* hsdram1.Init */
  hsdram1.Init.SDBank = FMC_SDRAM_BANK1;
  hsdram1.Init.ColumnBitsNumber = FMC_SDRAM_COLUMN_BITS_NUM_8;
  hsdram1.Init.RowBitsNumber = FMC_SDRAM_ROW_BITS_NUM_13;
  hsdram1.Init.MemoryDataWidth = FMC_SDRAM_MEM_BUS_WIDTH_16;
  hsdram1.Init.InternalBankNumber = FMC_SDRAM_INTERN_BANKS_NUM_4;
  hsdram1.Init.CASLatency = FMC_SDRAM_CAS_LATENCY_3;
  hsdram1.Init.WriteProtection = FMC_SDRAM_WRITE_PROTECTION_DISABLE;
  hsdram1.Init.SDClockPeriod = FMC_SDRAM_CLOCK_PERIOD_3;
  hsdram1.Init.ReadBurst = FMC_SDRAM_RBURST_DISABLE;
  hsdram1.Init.ReadPipeDelay = FMC_SDRAM_RPIPE_DELAY_0;
  /* SdramTiming */
  SdramTiming.LoadToActiveDelay = 3;
  SdramTiming.ExitSelfRefreshDelay = 4;
  SdramTiming.SelfRefreshTime = 2;
  SdramTiming.RowCycleDelay = 3;
  SdramTiming.WriteRecoveryTime = 2;
  SdramTiming.RPDelay = 1;
  SdramTiming.RCDDelay = 1;

  if (HAL_SDRAM_Init(&hsdram1, &SdramTiming) != HAL_OK)
  {
    _Error_Handler(__FILE__, __LINE__);
  }

}

/** Configure pins as
        * Analog
        * Input
        * Output
        * EVENT_OUT
        * EXTI
*/
static void MX_GPIO_Init(void)
{

  GPIO_InitTypeDef GPIO_InitStruct;

  /* GPIO Ports Clock Enable */
  __HAL_RCC_GPIOE_CLK_ENABLE();
  __HAL_RCC_GPIOC_CLK_ENABLE();
  __HAL_RCC_GPIOF_CLK_ENABLE();
  __HAL_RCC_GPIOH_CLK_ENABLE();
  __HAL_RCC_GPIOA_CLK_ENABLE();
  __HAL_RCC_GPIOB_CLK_ENABLE();
  __HAL_RCC_GPIOG_CLK_ENABLE();
  __HAL_RCC_GPIOD_CLK_ENABLE();

  /*Configure GPIO pin Output Level */
  HAL_GPIO_WritePin(GPIOE, MTR_TRQ1_Pin|MTR_SLEEP_Pin|MTR_STEP_Pin, GPIO_PIN_RESET);

  /*Configure GPIO pin Output Level */
  HAL_GPIO_WritePin(GPIOE, MTR_EN_Pin|MTR_RST_N_Pin, GPIO_PIN_SET);

  /*Configure GPIO pin Output Level */
  HAL_GPIO_WritePin(GPIOB, PH_STR_1_Pin|PH_LATCH_Pin|MTR_DIR_Pin|MTR_HOME_Pin, GPIO_PIN_RESET);

  /*Configure GPIO pin Output Level */
  HAL_GPIO_WritePin(GPIOB, LED_RED_N_Pin|LED_GRN_N_Pin, GPIO_PIN_SET);

  /*Configure GPIO pin Output Level */
  HAL_GPIO_WritePin(GPIOC, PH_POWER_OFF_Pin|WIFI_CHIP_EN_Pin, GPIO_PIN_RESET);

  /*Configure GPIO pin Output Level */
  HAL_GPIO_WritePin(GPIOA, PH_POWER_ON_Pin|USB_EN_Pin, GPIO_PIN_RESET);

  /*Configure GPIO pin Output Level */
  HAL_GPIO_WritePin(GPIOD, WIFI_RST_N_Pin|WIFI_WAKE_Pin, GPIO_PIN_RESET);

  /*Configure GPIO pin Output Level */
  HAL_GPIO_WritePin(GPIOG, MTR_USM0_Pin|MTR_USM1_Pin, GPIO_PIN_RESET);

  /*Configure GPIO pins : MTR_TRQ1_Pin MTR_SLEEP_Pin MTR_EN_Pin MTR_STEP_Pin
                           MTR_RST_N_Pin */
  GPIO_InitStruct.Pin = MTR_TRQ1_Pin|MTR_SLEEP_Pin|MTR_EN_Pin|MTR_STEP_Pin
                          |MTR_RST_N_Pin;
  GPIO_InitStruct.Mode = GPIO_MODE_OUTPUT_PP;
  GPIO_InitStruct.Pull = GPIO_NOPULL;
  GPIO_InitStruct.Speed = GPIO_SPEED_FREQ_LOW;
  HAL_GPIO_Init(GPIOE, &GPIO_InitStruct);

  /*Configure GPIO pins : NA_PC13_Pin NA_PC14_Pin NA_PC15_Pin NA_PC1_Pin
                           NA_PC5_Pin NA_PC7_Pin */
  GPIO_InitStruct.Pin = NA_PC13_Pin|NA_PC14_Pin|NA_PC15_Pin|NA_PC1_Pin
                          |NA_PC5_Pin|NA_PC7_Pin;
  GPIO_InitStruct.Mode = GPIO_MODE_INPUT;
  GPIO_InitStruct.Pull = GPIO_NOPULL;
  HAL_GPIO_Init(GPIOC, &GPIO_InitStruct);

  /*Configure GPIO pin : FEEDKEY_N_Pin */
  GPIO_InitStruct.Pin = FEEDKEY_N_Pin;
  GPIO_InitStruct.Mode = GPIO_MODE_INPUT;
  GPIO_InitStruct.Pull = GPIO_PULLUP;
  HAL_GPIO_Init(FEEDKEY_N_GPIO_Port, &GPIO_InitStruct);

  /*Configure GPIO pin : HEAD_OPEN_Pin */
  GPIO_InitStruct.Pin = HEAD_OPEN_Pin;
  GPIO_InitStruct.Mode = GPIO_MODE_INPUT;
  GPIO_InitStruct.Pull = GPIO_NOPULL;
  HAL_GPIO_Init(HEAD_OPEN_GPIO_Port, &GPIO_InitStruct);

  /*Configure GPIO pins : PH_STR_1_Pin PH_LATCH_Pin LED_RED_N_Pin LED_GRN_N_Pin
                           MTR_DIR_Pin MTR_HOME_Pin */
  GPIO_InitStruct.Pin = PH_STR_1_Pin|PH_LATCH_Pin|LED_RED_N_Pin|LED_GRN_N_Pin
                          |MTR_DIR_Pin|MTR_HOME_Pin;
  GPIO_InitStruct.Mode = GPIO_MODE_OUTPUT_PP;
  GPIO_InitStruct.Pull = GPIO_NOPULL;
  GPIO_InitStruct.Speed = GPIO_SPEED_FREQ_LOW;
  HAL_GPIO_Init(GPIOB, &GPIO_InitStruct);

  /*Configure GPIO pins : NA_PB12_Pin ID0_Pin ID1_Pin ID2_Pin
                           NA_PB5_Pin */
  GPIO_InitStruct.Pin = NA_PB12_Pin|ID0_Pin|ID1_Pin|ID2_Pin
                          |NA_PB5_Pin;
  GPIO_InitStruct.Mode = GPIO_MODE_INPUT;
  GPIO_InitStruct.Pull = GPIO_NOPULL;
  HAL_GPIO_Init(GPIOB, &GPIO_InitStruct);

  /*Configure GPIO pins : NA_PD11_Pin NA_PD13_Pin NA_PD6_Pin NA_PD7_Pin */
  GPIO_InitStruct.Pin = NA_PD11_Pin|NA_PD13_Pin|NA_PD6_Pin|NA_PD7_Pin;
  GPIO_InitStruct.Mode = GPIO_MODE_INPUT;
  GPIO_InitStruct.Pull = GPIO_NOPULL;
  HAL_GPIO_Init(GPIOD, &GPIO_InitStruct);

  /*Configure GPIO pins : NA_PG3_Pin NA_PG6_Pin NA_PG7_Pin */
  GPIO_InitStruct.Pin = NA_PG3_Pin|NA_PG6_Pin|NA_PG7_Pin;
  GPIO_InitStruct.Mode = GPIO_MODE_INPUT;
  GPIO_InitStruct.Pull = GPIO_NOPULL;
  HAL_GPIO_Init(GPIOG, &GPIO_InitStruct);

  /*Configure GPIO pin : PH_POWER_OFF_Pin */
  GPIO_InitStruct.Pin = PH_POWER_OFF_Pin;
  GPIO_InitStruct.Mode = GPIO_MODE_OUTPUT_PP;
  GPIO_InitStruct.Pull = GPIO_PULLUP;
  GPIO_InitStruct.Speed = GPIO_SPEED_FREQ_LOW;
  HAL_GPIO_Init(PH_POWER_OFF_GPIO_Port, &GPIO_InitStruct);

  /*Configure GPIO pin : WIFI_IRQ_N_Pin */
  GPIO_InitStruct.Pin = WIFI_IRQ_N_Pin;
  GPIO_InitStruct.Mode = GPIO_MODE_IT_RISING;
  GPIO_InitStruct.Pull = GPIO_NOPULL;
  HAL_GPIO_Init(WIFI_IRQ_N_GPIO_Port, &GPIO_InitStruct);

  /*Configure GPIO pin : WIFI_CHIP_EN_Pin */
  GPIO_InitStruct.Pin = WIFI_CHIP_EN_Pin;
  GPIO_InitStruct.Mode = GPIO_MODE_OUTPUT_PP;
  GPIO_InitStruct.Pull = GPIO_NOPULL;
  GPIO_InitStruct.Speed = GPIO_SPEED_FREQ_LOW;
  HAL_GPIO_Init(WIFI_CHIP_EN_GPIO_Port, &GPIO_InitStruct);

  /*Configure GPIO pins : PH_POWER_ON_Pin USB_EN_Pin */
  GPIO_InitStruct.Pin = PH_POWER_ON_Pin|USB_EN_Pin;
  GPIO_InitStruct.Mode = GPIO_MODE_OUTPUT_PP;
  GPIO_InitStruct.Pull = GPIO_NOPULL;
  GPIO_InitStruct.Speed = GPIO_SPEED_FREQ_LOW;
  HAL_GPIO_Init(GPIOA, &GPIO_InitStruct);

  /*Configure GPIO pins : WIFI_RST_N_Pin WIFI_WAKE_Pin */
  GPIO_InitStruct.Pin = WIFI_RST_N_Pin|WIFI_WAKE_Pin;
  GPIO_InitStruct.Mode = GPIO_MODE_OUTPUT_PP;
  GPIO_InitStruct.Pull = GPIO_NOPULL;
  GPIO_InitStruct.Speed = GPIO_SPEED_FREQ_LOW;
  HAL_GPIO_Init(GPIOD, &GPIO_InitStruct);

  /*Configure GPIO pins : MTR_USM0_Pin MTR_USM1_Pin */
  GPIO_InitStruct.Pin = MTR_USM0_Pin|MTR_USM1_Pin;
  GPIO_InitStruct.Mode = GPIO_MODE_OUTPUT_PP;
  GPIO_InitStruct.Pull = GPIO_NOPULL;
  GPIO_InitStruct.Speed = GPIO_SPEED_FREQ_LOW;
  HAL_GPIO_Init(GPIOG, &GPIO_InitStruct);

}

void _Error_Handler(char * file, int line)
{
  while(1)
  {
  }
}

/************************ (C) COPYRIGHT STMicroelectronics *****END OF FILE****/
